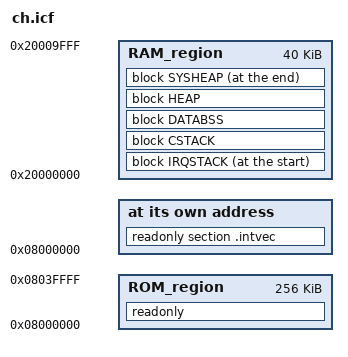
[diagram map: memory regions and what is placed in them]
/*###ICF### Section handled by ICF editor, don't touch! ****/
/*-Editor annotation file-*/
/* IcfEditorFile="$TOOLKIT_DIR$\config\ide\IcfEditor\cortex_v1_0.xml" */
/*-Specials-*/

define symbol __ICFEDIT_intvec_start__ = 0x08000000;

/*-Memory Regions-*/
define symbol __ICFEDIT_region_ROM_start__ = 0x08000000;
define symbol __ICFEDIT_region_ROM_end__   = 0x0803FFFF;
define symbol __ICFEDIT_region_RAM_start__ = 0x20000000;
define symbol __ICFEDIT_region_RAM_end__   = 0x20009FFF;

/*-Sizes-*/
define symbol __ICFEDIT_size_cstack__ = 0x400; /* Size of the process stack */
define symbol __ICFEDIT_size_heap__   = 0x100; /* Used to mark heap (heap + sysheap) maximum size limit */
/**** End of ICF editor section. ###ICF###*/

/* Size of the IRQ Stack (Main Stack).*/
define symbol __ICFEDIT_size_irqstack__   = 0x400;

define memory mem with size = 4G;
define region ROM_region   = mem:[from __ICFEDIT_region_ROM_start__   to __ICFEDIT_region_ROM_end__];
define region RAM_region   = mem:[from __ICFEDIT_region_RAM_start__   to __ICFEDIT_region_RAM_end__];

define block IRQSTACK  with alignment = 8, size = __ICFEDIT_size_irqstack__, fixed order { };
define block CSTACK    with alignment = 8, size = __ICFEDIT_size_cstack__,   fixed order {section CSTACK};
define block DATABSS   with alignment = 8,                                   fixed order {readwrite, zeroinit};
define block HEAP      with alignment = 8, size = __ICFEDIT_size_heap__,     fixed order {section HEAP};
define block SYSHEAP   with alignment = 8                                                {section SYSHEAP};

initialize by copy {readwrite};
do not initialize  {section .noinit};

keep { section .intvec };

place at address mem:__ICFEDIT_intvec_start__ {readonly section .intvec};

place in ROM_region                           {readonly};

place at start of RAM_region                  {block IRQSTACK}; /* Main stack which becomes IRQ stack */
place in RAM_region                           {block CSTACK};   /* Process stack */
place in RAM_region                           {block DATABSS};  /* Textdata region */
place in RAM_region                           {block HEAP};     /* Sys Heap size limit marker */
place at end of RAM_region                    {block SYSHEAP};  /* Sys Heap available for allocations */

/* Define stack and memory addresses for kernel usage */ 
define exported symbol __main_stack_base__        = __ICFEDIT_region_RAM_start__;
define exported symbol __main_stack_end__         = __main_stack_base__ + __ICFEDIT_size_irqstack__; /* Note: End refers to empty stack */
define exported symbol __process_stack_base__     = __main_stack_end__;
define exported symbol __main_thread_stack_base__ = __process_stack_base__;                          /* Note: Main thread uses process stack */
define exported symbol __process_stack_end__      = __process_stack_base__ + __ICFEDIT_size_cstack__;
